# XHSC_HC32L021 register map
Vendor: XHSC Co.Ltd; Series: ARMCM4; File version: 1.2
CPU: CM4 r0p0, little endian, no MPU, no FPU, 3 interrupt priority bits
Registers are 32-bit, read-write, reset 0x0 unless marked. A register's access mark holds for its fields unless they carry their own. Offsets are from the block's base; [hi:lo] are bit positions; {n}, {i} and the like mark numbered series; 'fields as' and 'values as' point back to an identical list.

## BTIM0 — desc BTIM
Base 0x40001800
Same registers: BTIM1 0x40001900, BTIM2 0x40001A00, BTIM3 0x40001C00, BTIM4 0x40001D00, BTIM5 0x40001E00
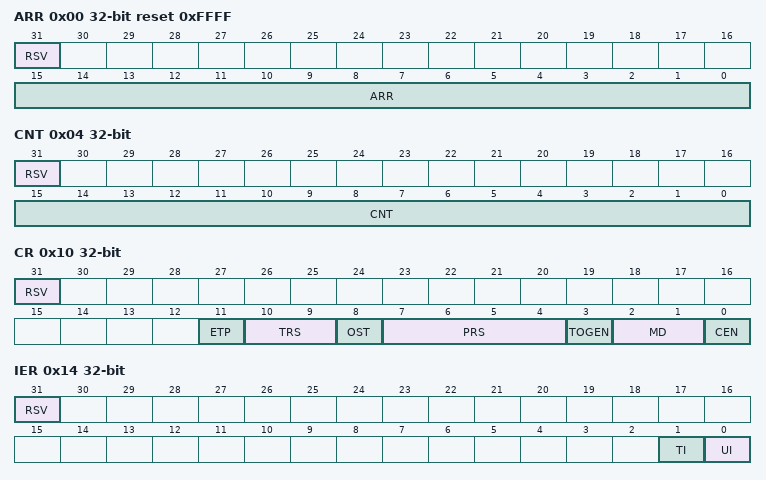
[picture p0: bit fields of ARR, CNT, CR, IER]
0x00 ARR reset 0xFFFF (reset mask 0xFFFF)
  [31] RSV, [15:0] ARR
0x04 CNT (reset mask 0xFFFF)
  [31] RSV, [15:0] CNT
0x10 CR (reset mask 0xFFF)
  [31] RSV, [11] ETP, [10:9] TRS, [8] OST, [7:4] PRS, [3] TOGEN, [2:1] MD, [0] CEN
0x14 IER (reset mask 0x3)
  [31] RSV, [1] TI, [0] UI
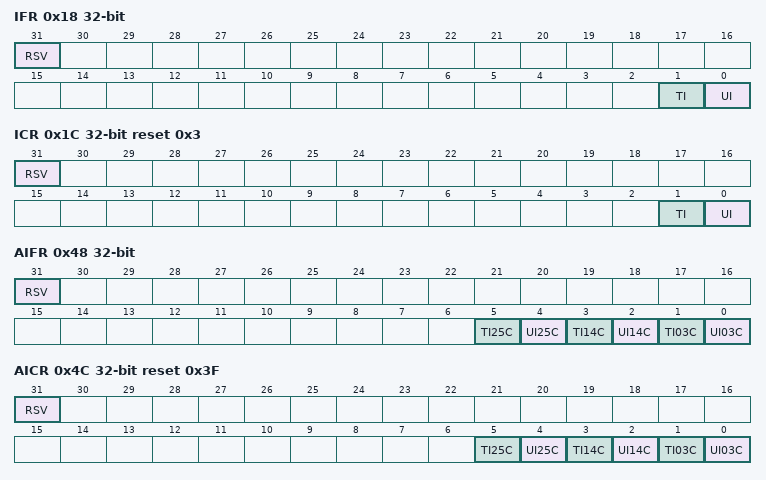
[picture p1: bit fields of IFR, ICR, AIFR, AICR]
0x18 IFR ro (reset mask 0x3)
  [31] RSV, [1] TI, [0] UI
0x1C ICR reset 0x3 (reset mask 0x3)
  [31] RSV, [1] TI, [0] UI
0x48 AIFR ro (reset mask 0x3F)
  [31] RSV, [5] TI25C, [4] UI25C, [3] TI14C, [2] UI14C, [1] TI03C, [0] UI03C
0x4C AICR reset 0x3F (reset mask 0x3F)
  fields as AIFR

## CTRIM
Base 0x40009000
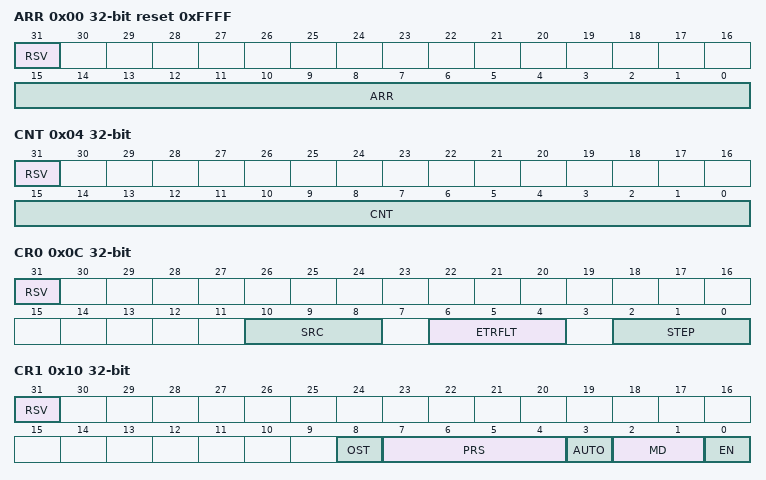
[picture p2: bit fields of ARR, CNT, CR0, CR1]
0x00 ARR reset 0xFFFF (reset mask 0xFFFF)
  [31] RSV, [15:0] ARR
0x04 CNT ro (reset mask 0xFFFF)
  [31] RSV, [15:0] CNT
0x0C CR0 (reset mask 0x777)
  [31] RSV, [10:8] SRC, [6:4] ETRFLT, [2:0] STEP
0x10 CR1 (reset mask 0x7FF)
  [31] RSV, [8] OST, [7:4] PRS, [3] AUTO, [2:1] MD, [0] EN
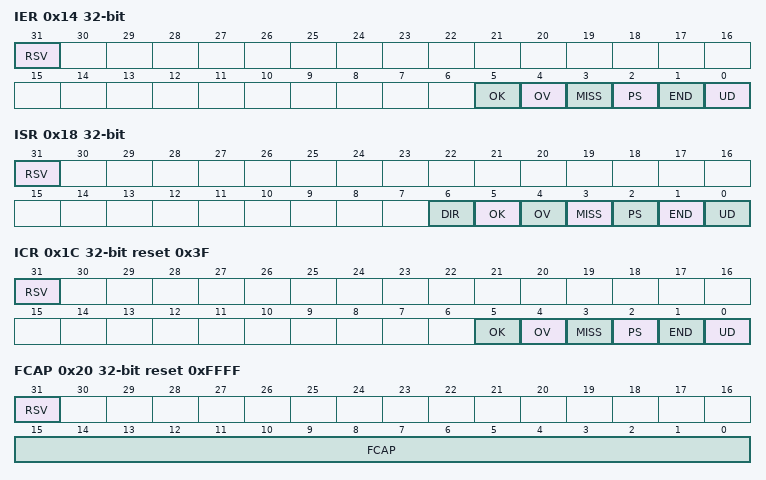
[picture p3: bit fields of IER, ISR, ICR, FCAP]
0x14 IER (reset mask 0x3F)
  [31] RSV, [5] OK, [4] OV, [3] MISS, [2] PS, [1] END, [0] UD
0x18 ISR ro (reset mask 0x7F)
  [31] RSV, [6] DIR, [5] OK, [4] OV, [3] MISS, [2] PS, [1] END, [0] UD
0x1C ICR wo reset 0x3F (reset mask 0x3F)
  [31] RSV, [5] OK, [4] OV, [3] MISS, [2] PS, [1] END, [0] UD
0x20 FCAP ro reset 0xFFFF (reset mask 0xFFFF)
  [31] RSV, [15:0] FCAP
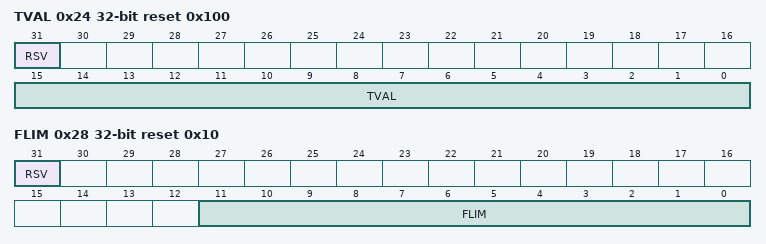
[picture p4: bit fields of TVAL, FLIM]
0x24 TVAL ro reset 0x100 (reset mask 0xFFFF)
  [31] RSV, [15:0] TVAL
0x28 FLIM reset 0x10 (reset mask 0xFFF)
  [31] RSV, [11:0] FLIM

## FLASH
Base 0x40020000
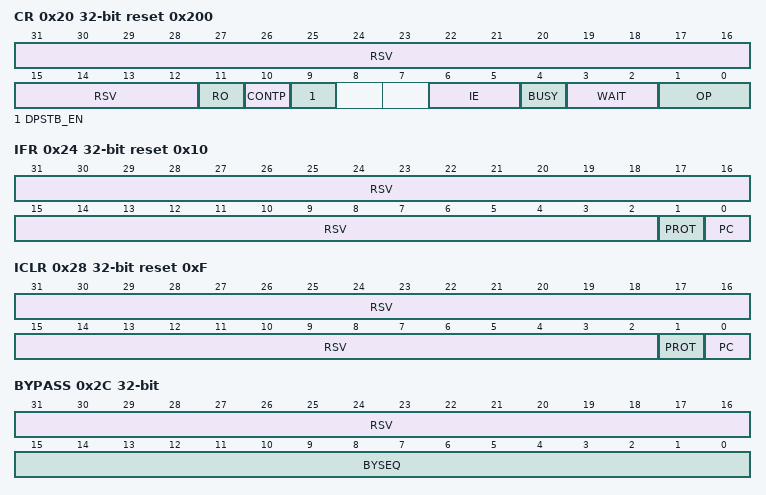
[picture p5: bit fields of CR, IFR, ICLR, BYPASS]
0x20 CR reset 0x200 (reset mask 0xE7F)
  [31:12] RSV, [11] RO, [10] CONTP, [9] DPSTB_EN, [6:5] IE, [4] BUSY ro, [3:2] WAIT, [1:0] OP
0x24 IFR ro reset 0x10 (reset mask 0x3)
  [31:2] RSV, [1] PROT, [0] PC
0x28 ICLR wo reset 0xF (reset mask 0x3)
  [31:2] RSV, [1] PROT, [0] PC
0x2C BYPASS wo (reset mask 0xFFFF)
  [31:16] RSV rw, [15:0] BYSEQ
0x30 SLOCK0
  [31:0] SLOCK
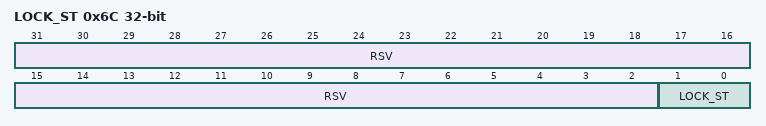
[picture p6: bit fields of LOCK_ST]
0x6C LOCK_ST ro (reset mask 0x3)
  [31:2] RSV rw, [1:0] LOCK_ST

## GPIOA — desc GPIO
Base 0x40020C00
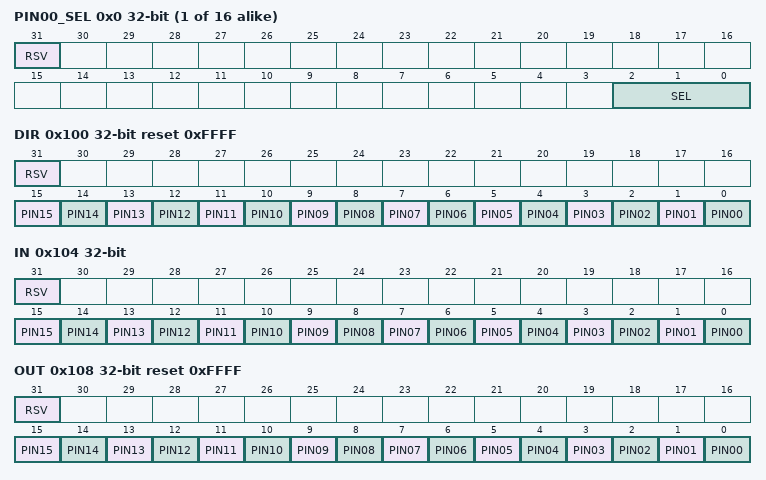
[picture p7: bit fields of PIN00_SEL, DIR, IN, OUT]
{0x0+4i} PIN{i:02}_SEL (reset mask 0x7) (i=0..15)
  [31] RSV, [2:0] SEL
0x100 DIR reset 0xFFFF (reset mask 0xFFFF)
  [31] RSV, [n] PIN{n:02} (n=0..15)
0x104 IN ro (reset mask 0xFFFF)
  [31] RSV, [n] PIN{n:02} (n=0..15)
0x108 OUT reset 0xFFFF (reset mask 0xFFFF)
  [31] RSV, [n] PIN{n:02} (n=0..15)
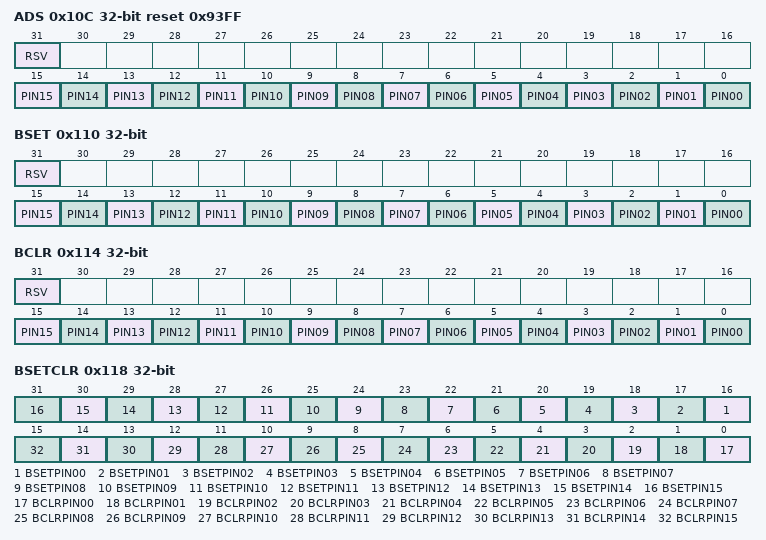
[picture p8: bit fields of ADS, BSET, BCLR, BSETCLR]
0x10C ADS reset 0x93FF (reset mask 0xFFFF)
  [31] RSV, [n] PIN{n:02} (n=0..15)
0x110 BSET wo (reset mask 0xFFFF)
  [31] RSV, [n] PIN{n:02} (n=0..15)
0x114 BCLR wo (reset mask 0xFFFF)
  [31] RSV, [n] PIN{n:02} (n=0..15)
0x118 BSETCLR wo
  [n+16] BSETPIN{n:02} (n=0..15), [n] BCLRPIN{n:02} (n=0..15)
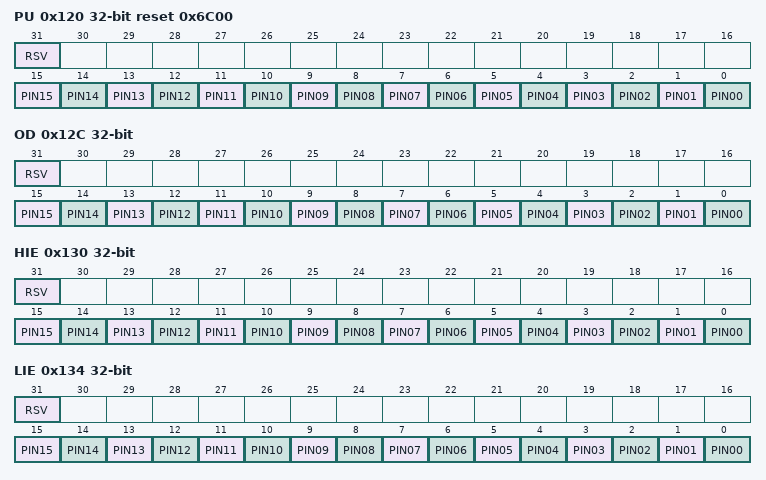
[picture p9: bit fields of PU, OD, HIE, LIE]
0x120 PU reset 0x6C00 (reset mask 0xFFFF)
  [31] RSV, [n] PIN{n:02} (n=0..15)
0x12C OD (reset mask 0xFFFF)
  [31] RSV, [n] PIN{n:02} (n=0..15)
0x130 HIE (reset mask 0xFFFF)
  [31] RSV, [n] PIN{n:02} (n=0..15)
0x134 LIE (reset mask 0xFFFF)
  [31] RSV, [n] PIN{n:02} (n=0..15)
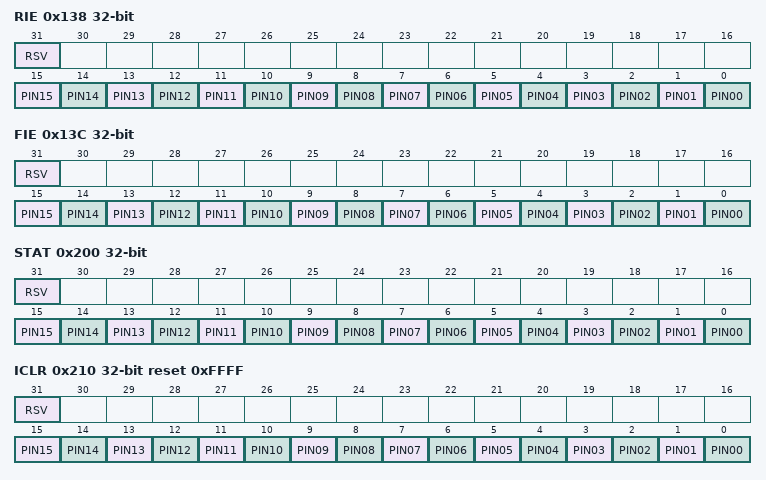
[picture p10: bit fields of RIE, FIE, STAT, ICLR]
0x138 RIE (reset mask 0xFFFF)
  [31] RSV, [n] PIN{n:02} (n=0..15)
0x13C FIE (reset mask 0xFFFF)
  [31] RSV, [n] PIN{n:02} (n=0..15)
0x200 STAT ro (reset mask 0xFFFF)
  [31] RSV, [n] PIN{n:02} (n=0..15)
0x210 ICLR reset 0xFFFF (reset mask 0xFFFF)
  [31] RSV, [n] PIN{n:02} (n=0..15)

## GPIOB — desc GPIO
Base 0x40020C40
Registers as GPIOA, without PIN{n:02}_SEL (n=1..15), DIR, OUT, ADS, BSET, BCLR, BSETCLR, PU, OD.

## GPIOAUX
Base 0x40020C00; alternate view of GPIOA
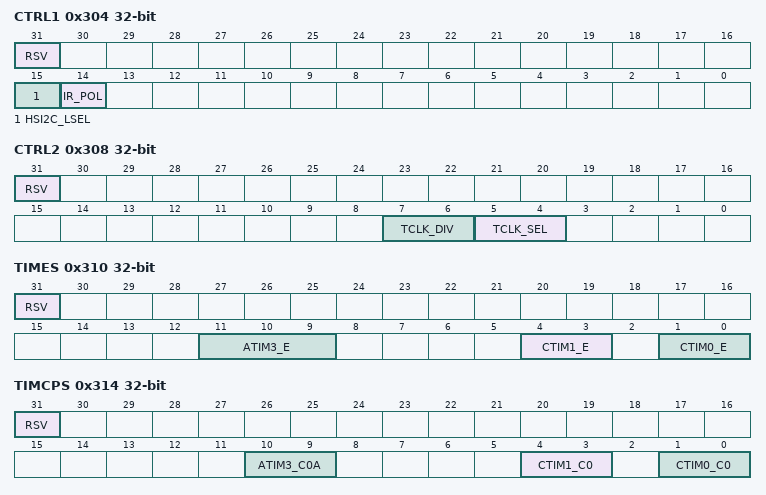
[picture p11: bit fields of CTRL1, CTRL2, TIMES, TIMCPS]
0x304 CTRL1 (reset mask 0x7FFF)
  [31] RSV, [15] HSI2C_LSEL, [14] IR_POL
0x308 CTRL2 (reset mask 0x80FF)
  [31] RSV, [7:6] TCLK_DIV, [5:4] TCLK_SEL
0x310 TIMES (reset mask 0x7FFF)
  [31] RSV, [11:9] ATIM3_E, [4:3] CTIM1_E, [1:0] CTIM0_E
0x314 TIMCPS (reset mask 0x7FFF)
  [31] RSV, [10:9] ATIM3_C0A, [4:3] CTIM1_C0, [1:0] CTIM0_C0
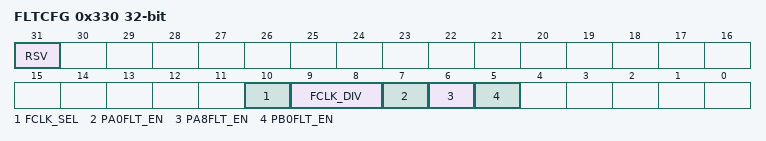
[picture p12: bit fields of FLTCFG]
0x330 FLTCFG (reset mask 0xFFF)
  [31] RSV, [10] FCLK_SEL, [9:8] FCLK_DIV, [7] PA0FLT_EN, [6] PA8FLT_EN, [5] PB0FLT_EN
